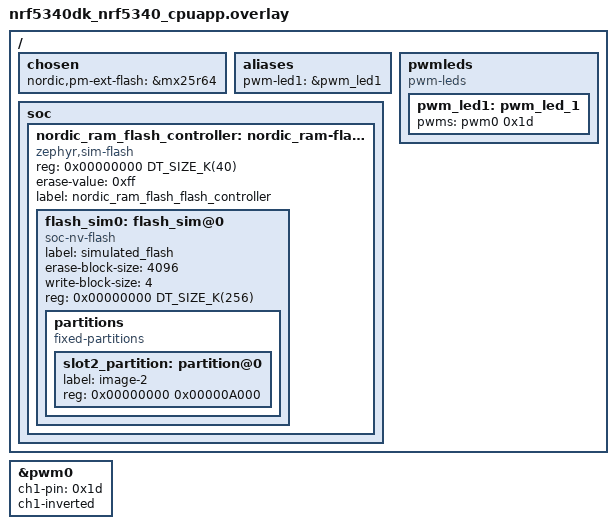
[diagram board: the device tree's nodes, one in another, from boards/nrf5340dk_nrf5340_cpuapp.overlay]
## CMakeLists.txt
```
#
# Copyright (c) 2021 Nordic Semiconductor ASA
#
# SPDX-License-Identifier: LicenseRef-Nordic-5-Clause
#

cmake_minimum_required(VERSION 3.20.0)

if(BOARD STREQUAL "nrf52840dk_nrf52840" OR BOARD STREQUAL "nrf5340dk_nrf5340_cpuapp")
    set(BUILD_WITH_DFU "MATTER" CACHE STRING "Build target with Device Firmware Upgrade support")
else()
    set(BUILD_WITH_DFU "OFF" CACHE STRING "Build target with Device Firmware Upgrade support")
endif()

if(NOT BUILD_WITH_DFU STREQUAL "OFF")
    if(BUILD_WITH_DFU STREQUAL "BLE" AND BOARD STREQUAL "nrf5340dk_nrf5340_cpuapp")
        set(CONF_FILE prj_multi_image_smp_dfu.conf)
    elseif(BUILD_WITH_DFU STREQUAL "BLE")
        set(CONF_FILE prj_single_image_smp_dfu.conf)
    elseif(BUILD_WITH_DFU STREQUAL "MATTER" AND BOARD STREQUAL "nrf5340dk_nrf5340_cpuapp")
        set(CONF_FILE prj_multi_image_matter_dfu.conf)
    elseif(BUILD_WITH_DFU STREQUAL "MATTER")
        set(CONF_FILE prj_single_image_matter_dfu.conf)
    else()
        message(FATAL_ERROR "Selected invalid BUILD_WITH_DFU value: ${BUILD_WITH_DFU}")
    endif()

    if (EXISTS "${CMAKE_CURRENT_SOURCE_DIR}/configuration/${BOARD}/pm_static.yml")
        set(PM_STATIC_YML_FILE ${CMAKE_CURRENT_SOURCE_DIR}/configuration/${BOARD}/pm_static.yml)
    else()
        message(FATAL_ERROR "The ${BOARD} target does not support DFU")
    endif()
endif()

find_package(Zephyr HINTS $ENV{ZEPHYR_BASE})

project(matter-light-bulb)

set(COMMON_ROOT ${ZEPHYR_NRF_MODULE_DIR}/samples/matter/common)
set(NLIO_ROOT ${ZEPHYR_CONNECTEDHOMEIP_MODULE_DIR}/third_party/nlio/repo)
include(${ZEPHYR_CONNECTEDHOMEIP_MODULE_DIR}/config/nrfconnect/app/enable-gnu-std.cmake)
include(${ZEPHYR_CONNECTEDHOMEIP_MODULE_DIR}/src/app/chip_data_model.cmake)

# NORDIC SDK APP START
target_include_directories(app PRIVATE
    src
    ${COMMON_ROOT}/src
    ${NLIO_ROOT}/include
    ${ZEPHYR_CONNECTEDHOMEIP_MODULE_DIR}/zzz_generated/app-common
)

target_sources(app PRIVATE
    src/app_task.cpp
    src/lighting_manager.cpp
    src/light_bulb_publish_service.cpp
    src/main.cpp
    src/zcl_callbacks.cpp
    src/zap-generated/IMClusterCommandHandler.cpp
    src/zap-generated/callback-stub.cpp
    ${COMMON_ROOT}/src/led_widget.cpp
    ${COMMON_ROOT}/src/thread_util.cpp
)

if(BUILD_WITH_DFU STREQUAL "BLE")
    target_sources(app PRIVATE ${COMMON_ROOT}/src/dfu_over_smp.cpp)
endif()

chip_configure_data_model(app
    INCLUDE_SERVER
    ZAP_FILE ${CMAKE_CURRENT_SOURCE_DIR}/src/light_bulb.zap
)
# NORDIC SDK APP END
```

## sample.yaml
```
sample:
  name: Matter Light Bulb
  description: Matter Light Bulb example
tests:
  matter.light_bulb:
    build_only: true
    platform_allow: nrf52840dk_nrf52840 nrf5340dk_nrf5340_cpuapp nrf21540dk_nrf52840
    integration_platforms:
      - nrf52840dk_nrf52840
      - nrf5340dk_nrf5340_cpuapp
      - nrf21540dk_nrf52840
    tags: ci_build
  matter.light_bulb.smp_dfu:
    build_only: true
    platform_allow: nrf52840dk_nrf52840 nrf5340dk_nrf5340_cpuapp
    integration_platforms:
      - nrf52840dk_nrf52840
      - nrf5340dk_nrf5340_cpuapp
    tags: ci_build
    extra_args: "BUILD_WITH_DFU=BLE"
```

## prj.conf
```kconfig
#
# Copyright (c) 2021 Nordic Semiconductor ASA
#
# SPDX-License-Identifier: LicenseRef-Nordic-5-Clause
#

# Enable CHIP
CONFIG_CHIP=y
CONFIG_CHIP_PROJECT_CONFIG="src/chip_project_config.h"
CONFIG_STD_CPP14=y

# Enable CHIP pairing automatically on application start.
CONFIG_CHIP_ENABLE_PAIRING_AUTOSTART=y

# General networking settings
CONFIG_NETWORKING=y
CONFIG_NET_IPV6_NBR_CACHE=n
CONFIG_NET_IPV6_MLD=n
CONFIG_NET_SOCKETS_POLL_MAX=5

# Enable OpenThread MTD
CONFIG_NET_L2_OPENTHREAD=y

CONFIG_OPENTHREAD_MTD=y
CONFIG_OPENTHREAD_FTD=n
CONFIG_OPENTHREAD_SLAAC=y
CONFIG_OPENTHREAD_MTD_NETDIAG=y
CONFIG_OPENTHREAD_MANUAL_START=y
CONFIG_OPENTHREAD_THREAD_STACK_SIZE=6144
CONFIG_OPENTHREAD_NUM_MESSAGE_BUFFERS=64

CONFIG_OPENTHREAD_PANID=4660
CONFIG_OPENTHREAD_CHANNEL=15
CONFIG_OPENTHREAD_NETWORK_NAME="OpenThread"
CONFIG_OPENTHREAD_XPANID="11:11:11:11:22:22:22:22"

# Enable Thread 1.2 features
CONFIG_OPENTHREAD_THREAD_VERSION_1_2=y
CONFIG_OPENTHREAD_DUA=y
CONFIG_OPENTHREAD_MLR=y

# Enable Bluetooth Low Energy
CONFIG_BT=y
CONFIG_BT_PERIPHERAL=y
CONFIG_BT_PERIPHERAL_PREF_MIN_INT=12
CONFIG_BT_PERIPHERAL_PREF_MAX_INT=12
CONFIG_BT_GAP_AUTO_UPDATE_CONN_PARAMS=y
CONFIG_BT_GATT_DYNAMIC_DB=y
CONFIG_BT_DEVICE_APPEARANCE=0
CONFIG_BT_DEVICE_NAME_DYNAMIC=y
CONFIG_BT_DEVICE_NAME_MAX=15
CONFIG_BT_DEVICE_NAME="MatterLight"
CONFIG_BT_MAX_CONN=1
CONFIG_BT_L2CAP_TX_MTU=247
CONFIG_BT_BUF_ACL_RX_SIZE=251
CONFIG_BT_BUF_ACL_TX_SIZE=251

# Use NFC to share commissioning information
CONFIG_CHIP_NFC_COMMISSIONING=y

# Use nrf_security
CONFIG_OPENTHREAD_NRF_SECURITY_CHOICE=y

CONFIG_CC3XX_BACKEND=n
CONFIG_OBERON_BACKEND=y

CONFIG_MBEDTLS_ENABLE_HEAP=y
CONFIG_MBEDTLS_HEAP_SIZE=15360
CONFIG_MBEDTLS_TLS_LIBRARY=y
CONFIG_NRF_SECURITY_ADVANCED=y

CONFIG_MBEDTLS_AES_C=y
CONFIG_MBEDTLS_ECP_C=y
CONFIG_MBEDTLS_ECP_DP_SECP256R1_ENABLED=y
CONFIG_MBEDTLS_CTR_DRBG_C=y
CONFIG_MBEDTLS_CIPHER_MODE_CTR=y
CONFIG_MBEDTLS_ECJPAKE_C=y
CONFIG_MBEDTLS_SHA256_C=y
CONFIG_MBEDTLS_PK_C=y
CONFIG_MBEDTLS_PK_WRITE_C=y
CONFIG_MBEDTLS_X509_CREATE_C=y
CONFIG_MBEDTLS_X509_CSR_WRITE_C=y

# Disable unneeded crypto operations
CONFIG_MBEDTLS_SHA384_C=n
CONFIG_MBEDTLS_SHA512_C=n
CONFIG_MBEDTLS_CIPHER_MODE_XTS=n
CONFIG_MBEDTLS_CHACHA20_C=n
CONFIG_MBEDTLS_POLY1305_C=n
CONFIG_MBEDTLS_CHACHAPOLY_C=n
CONFIG_MBEDTLS_GCM_C=n
CONFIG_MBEDTLS_RSA_C=n

# Add support for LEDs and buttons on Nordic development kits
CONFIG_DK_LIBRARY=y
CONFIG_PWM=y

# Other settings
CONFIG_LOG=y
CONFIG_LOG_MODE_MINIMAL=y
CONFIG_MATTER_LOG_LEVEL_DBG=y
CONFIG_PRINTK_SYNC=y
CONFIG_MAIN_STACK_SIZE=8192
CONFIG_INIT_STACKS=y
CONFIG_HW_STACK_PROTECTION=y
CONFIG_HWINFO=y
CONFIG_THREAD_NAME=y
CONFIG_SHELL=y
CONFIG_ASSERT=y
```

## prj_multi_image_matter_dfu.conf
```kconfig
#
# Copyright (c) 2022 Nordic Semiconductor ASA
#
# SPDX-License-Identifier: LicenseRef-Nordic-5-Clause
#

# Enable CHIP
CONFIG_CHIP=y
CONFIG_CHIP_PROJECT_CONFIG="src/chip_project_config.h"
CONFIG_STD_CPP14=y

# Enable CHIP pairing automatically on application start.
CONFIG_CHIP_ENABLE_PAIRING_AUTOSTART=y

# General networking settings
CONFIG_NETWORKING=y
CONFIG_NET_IPV6_NBR_CACHE=n
CONFIG_NET_IPV6_MLD=n
CONFIG_NET_SOCKETS_POLL_MAX=5

# Enable OpenThread MTD
CONFIG_NET_L2_OPENTHREAD=y

CONFIG_OPENTHREAD_MTD=y
CONFIG_OPENTHREAD_FTD=n
CONFIG_OPENTHREAD_SLAAC=y
CONFIG_OPENTHREAD_MTD_NETDIAG=y
CONFIG_OPENTHREAD_MANUAL_START=y
CONFIG_OPENTHREAD_THREAD_STACK_SIZE=6144
CONFIG_OPENTHREAD_NUM_MESSAGE_BUFFERS=64

CONFIG_OPENTHREAD_PANID=4660
CONFIG_OPENTHREAD_CHANNEL=15
CONFIG_OPENTHREAD_NETWORK_NAME="OpenThread"
CONFIG_OPENTHREAD_XPANID="11:11:11:11:22:22:22:22"

# Enable Thread 1.2 features
CONFIG_OPENTHREAD_THREAD_VERSION_1_2=y
CONFIG_OPENTHREAD_DUA=y
CONFIG_OPENTHREAD_MLR=y

# Enable Bluetooth Low Energy
CONFIG_BT=y
CONFIG_BT_PERIPHERAL=y
CONFIG_BT_PERIPHERAL_PREF_MIN_INT=12
CONFIG_BT_PERIPHERAL_PREF_MAX_INT=12
CONFIG_BT_GAP_AUTO_UPDATE_CONN_PARAMS=y
CONFIG_BT_GATT_DYNAMIC_DB=y
CONFIG_BT_DEVICE_APPEARANCE=0
CONFIG_BT_DEVICE_NAME_DYNAMIC=y
CONFIG_BT_DEVICE_NAME_MAX=15
CONFIG_BT_DEVICE_NAME="MatterLight"
CONFIG_BT_MAX_CONN=1
CONFIG_BT_L2CAP_TX_MTU=247
CONFIG_BT_BUF_ACL_RX_SIZE=251
CONFIG_BT_BUF_ACL_TX_SIZE=251

# Use NFC to share commissioning information
CONFIG_CHIP_NFC_COMMISSIONING=y

# Use nrf_security
CONFIG_OPENTHREAD_NRF_SECURITY_CHOICE=y

CONFIG_CC3XX_BACKEND=n
CONFIG_OBERON_BACKEND=y

CONFIG_MBEDTLS_ENABLE_HEAP=y
CONFIG_MBEDTLS_HEAP_SIZE=15360
CONFIG_MBEDTLS_TLS_LIBRARY=y
CONFIG_NRF_SECURITY_ADVANCED=y

CONFIG_MBEDTLS_AES_C=y
CONFIG_MBEDTLS_ECP_C=y
CONFIG_MBEDTLS_ECP_DP_SECP256R1_ENABLED=y
CONFIG_MBEDTLS_CTR_DRBG_C=y
CONFIG_MBEDTLS_CIPHER_MODE_CTR=y
CONFIG_MBEDTLS_ECJPAKE_C=y
CONFIG_MBEDTLS_SHA256_C=y
CONFIG_MBEDTLS_PK_C=y
CONFIG_MBEDTLS_PK_WRITE_C=y
CONFIG_MBEDTLS_X509_CREATE_C=y
CONFIG_MBEDTLS_X509_CSR_WRITE_C=y

# Disable unneeded crypto operations
CONFIG_MBEDTLS_SHA384_C=n
CONFIG_MBEDTLS_SHA512_C=n
CONFIG_MBEDTLS_CIPHER_MODE_XTS=n
CONFIG_MBEDTLS_CHACHA20_C=n
CONFIG_MBEDTLS_POLY1305_C=n
CONFIG_MBEDTLS_CHACHAPOLY_C=n
CONFIG_MBEDTLS_GCM_C=n
CONFIG_MBEDTLS_RSA_C=n

# Add support for LEDs and buttons on Nordic development kits
CONFIG_DK_LIBRARY=y
CONFIG_PWM=y

# Other settings
CONFIG_LOG=y
CONFIG_LOG_MODE_MINIMAL=y
CONFIG_MATTER_LOG_LEVEL_DBG=y
CONFIG_PRINTK_SYNC=y
CONFIG_MAIN_STACK_SIZE=8192
CONFIG_INIT_STACKS=y
CONFIG_HW_STACK_PROTECTION=y
CONFIG_HWINFO=y
CONFIG_THREAD_NAME=y
CONFIG_SHELL=y
CONFIG_ASSERT=y

# Enable bootloader and DFU related configs
CONFIG_BOOTLOADER_MCUBOOT=y
CONFIG_UPDATEABLE_IMAGE_NUMBER=2

# QSPI configuration
CONFIG_NORDIC_QSPI_NOR=y
CONFIG_NORDIC_QSPI_NOR_FLASH_LAYOUT_PAGE_SIZE=4096
CONFIG_NORDIC_QSPI_NOR_STACK_WRITE_BUFFER_SIZE=16

# FLASH nop device is needed to access network core image data.
CONFIG_FLASH_NOP_DEVICE=y

# Enable Matter OTA
CONFIG_CHIP_OTA_REQUESTOR=y
CONFIG_IMG_MANAGER=y
```

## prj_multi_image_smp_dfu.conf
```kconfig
#
# Copyright (c) 2021 Nordic Semiconductor ASA
#
# SPDX-License-Identifier: LicenseRef-Nordic-5-Clause
#

# Enable CHIP
CONFIG_CHIP=y
CONFIG_CHIP_PROJECT_CONFIG="src/chip_project_config.h"
CONFIG_STD_CPP14=y

# Enable CHIP pairing automatically on application start.
CONFIG_CHIP_ENABLE_PAIRING_AUTOSTART=y

# General networking settings
CONFIG_NETWORKING=y
CONFIG_NET_IPV6_NBR_CACHE=n
CONFIG_NET_IPV6_MLD=n
CONFIG_NET_SOCKETS_POLL_MAX=5

# Enable OpenThread MTD
CONFIG_NET_L2_OPENTHREAD=y

CONFIG_OPENTHREAD_MTD=y
CONFIG_OPENTHREAD_FTD=n
CONFIG_OPENTHREAD_SLAAC=y
CONFIG_OPENTHREAD_MTD_NETDIAG=y
CONFIG_OPENTHREAD_MANUAL_START=y
CONFIG_OPENTHREAD_THREAD_STACK_SIZE=6144
CONFIG_OPENTHREAD_NUM_MESSAGE_BUFFERS=64

CONFIG_OPENTHREAD_PANID=4660
CONFIG_OPENTHREAD_CHANNEL=15
CONFIG_OPENTHREAD_NETWORK_NAME="OpenThread"
CONFIG_OPENTHREAD_XPANID="11:11:11:11:22:22:22:22"

# Enable Thread 1.2 features
CONFIG_OPENTHREAD_THREAD_VERSION_1_2=y
CONFIG_OPENTHREAD_DUA=y
CONFIG_OPENTHREAD_MLR=y

# Enable Bluetooth Low Energy
CONFIG_BT=y
CONFIG_BT_PERIPHERAL=y
CONFIG_BT_PERIPHERAL_PREF_MIN_INT=12
CONFIG_BT_PERIPHERAL_PREF_MAX_INT=12
CONFIG_BT_GAP_AUTO_UPDATE_CONN_PARAMS=y
CONFIG_BT_GATT_DYNAMIC_DB=y
CONFIG_BT_DEVICE_APPEARANCE=0
CONFIG_BT_DEVICE_NAME_DYNAMIC=y
CONFIG_BT_DEVICE_NAME_MAX=15
CONFIG_BT_DEVICE_NAME="MatterLight"
CONFIG_BT_MAX_CONN=1

# Use NFC to share commissioning information
CONFIG_CHIP_NFC_COMMISSIONING=y

# Use nrf_security
CONFIG_OPENTHREAD_NRF_SECURITY_CHOICE=y

CONFIG_CC3XX_BACKEND=n
CONFIG_OBERON_BACKEND=y

CONFIG_MBEDTLS_ENABLE_HEAP=y
CONFIG_MBEDTLS_HEAP_SIZE=15360
CONFIG_MBEDTLS_TLS_LIBRARY=y
CONFIG_NRF_SECURITY_ADVANCED=y

CONFIG_MBEDTLS_AES_C=y
CONFIG_MBEDTLS_ECP_C=y
CONFIG_MBEDTLS_ECP_DP_SECP256R1_ENABLED=y
CONFIG_MBEDTLS_CTR_DRBG_C=y
CONFIG_MBEDTLS_CIPHER_MODE_CTR=y
CONFIG_MBEDTLS_ECJPAKE_C=y
CONFIG_MBEDTLS_SHA256_C=y
CONFIG_MBEDTLS_PK_C=y
CONFIG_MBEDTLS_PK_WRITE_C=y
CONFIG_MBEDTLS_X509_CREATE_C=y
CONFIG_MBEDTLS_X509_CSR_WRITE_C=y

# Disable unneeded crypto operations
CONFIG_MBEDTLS_SHA384_C=n
CONFIG_MBEDTLS_SHA512_C=n
CONFIG_MBEDTLS_CIPHER_MODE_XTS=n
CONFIG_MBEDTLS_CHACHA20_C=n
CONFIG_MBEDTLS_POLY1305_C=n
CONFIG_MBEDTLS_CHACHAPOLY_C=n
CONFIG_MBEDTLS_GCM_C=n
CONFIG_MBEDTLS_RSA_C=n

# Add support for LEDs and buttons on Nordic development kits
CONFIG_DK_LIBRARY=y
CONFIG_PWM=y

# Other settings
CONFIG_LOG=y
CONFIG_LOG_MODE_MINIMAL=y
CONFIG_MATTER_LOG_LEVEL_DBG=y
CONFIG_PRINTK_SYNC=y
CONFIG_MAIN_STACK_SIZE=8192
CONFIG_INIT_STACKS=y
CONFIG_HW_STACK_PROTECTION=y
CONFIG_HWINFO=y
CONFIG_THREAD_NAME=y
CONFIG_SHELL=y
CONFIG_ASSERT=y

# Enable bootloader and DFU related configs
CONFIG_BOOTLOADER_MCUBOOT=y
CONFIG_UPDATEABLE_IMAGE_NUMBER=2

# QSPI configuration
CONFIG_NORDIC_QSPI_NOR=y
CONFIG_NORDIC_QSPI_NOR_FLASH_LAYOUT_PAGE_SIZE=4096
CONFIG_NORDIC_QSPI_NOR_STACK_WRITE_BUFFER_SIZE=16

# MCU Manager and SMP configuration
CONFIG_MCUMGR=y
CONFIG_MCUMGR_CMD_IMG_MGMT=y
CONFIG_MCUMGR_CMD_OS_MGMT=y
CONFIG_MCUMGR_SMP_BT=y
CONFIG_MCUMGR_SMP_BT_AUTHEN=n
CONFIG_MCUMGR_BUF_COUNT=6

# Increase BT MTU and RX buffer for big size DFU messages
CONFIG_BT_L2CAP_TX_MTU=498
CONFIG_BT_BUF_ACL_TX_SIZE=251
CONFIG_BT_BUF_ACL_RX_SIZE=502

# Increase max number of pending GATT notification callbacks
CONFIG_BT_CONN_TX_MAX=6

# Increase system workqueue size, as SMP is processed within it
CONFIG_SYSTEM_WORKQUEUE_STACK_SIZE=2800

# FLASH nop device is enabled to prevent bus faults when mcumgr tries to access
# simulated partition with network core image data.
CONFIG_FLASH_NOP_DEVICE=y

# Enable custom SMP request to erase settings partition.
CONFIG_MCUMGR_GRP_ZEPHYR_BASIC=y
CONFIG_MCUMGR_GRP_BASIC_CMD_STORAGE_ERASE=y

# Enable Matter OTA
CONFIG_CHIP_OTA_REQUESTOR=y
```

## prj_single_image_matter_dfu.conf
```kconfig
#
# Copyright (c) 2022 Nordic Semiconductor ASA
#
# SPDX-License-Identifier: LicenseRef-Nordic-5-Clause
#

# Enable CHIP
CONFIG_CHIP=y
CONFIG_CHIP_PROJECT_CONFIG="src/chip_project_config.h"
CONFIG_STD_CPP14=y

# Enable CHIP pairing automatically on application start.
CONFIG_CHIP_ENABLE_PAIRING_AUTOSTART=y

# General networking settings
CONFIG_NETWORKING=y
CONFIG_NET_IPV6_NBR_CACHE=n
CONFIG_NET_IPV6_MLD=n
CONFIG_NET_SOCKETS_POLL_MAX=5

# Enable OpenThread MTD
CONFIG_NET_L2_OPENTHREAD=y

CONFIG_OPENTHREAD_MTD=y
CONFIG_OPENTHREAD_FTD=n
CONFIG_OPENTHREAD_SLAAC=y
CONFIG_OPENTHREAD_MTD_NETDIAG=y
CONFIG_OPENTHREAD_MANUAL_START=y
CONFIG_OPENTHREAD_THREAD_STACK_SIZE=6144
CONFIG_OPENTHREAD_NUM_MESSAGE_BUFFERS=64

CONFIG_OPENTHREAD_PANID=4660
CONFIG_OPENTHREAD_CHANNEL=15
CONFIG_OPENTHREAD_NETWORK_NAME="OpenThread"
CONFIG_OPENTHREAD_XPANID="11:11:11:11:22:22:22:22"

# Enable Thread 1.2 features
CONFIG_OPENTHREAD_THREAD_VERSION_1_2=y
CONFIG_OPENTHREAD_DUA=y
CONFIG_OPENTHREAD_MLR=y

# Enable Bluetooth Low Energy
CONFIG_BT=y
CONFIG_BT_PERIPHERAL=y
CONFIG_BT_PERIPHERAL_PREF_MIN_INT=12
CONFIG_BT_PERIPHERAL_PREF_MAX_INT=12
CONFIG_BT_GAP_AUTO_UPDATE_CONN_PARAMS=y
CONFIG_BT_GATT_DYNAMIC_DB=y
CONFIG_BT_DEVICE_APPEARANCE=0
CONFIG_BT_DEVICE_NAME_DYNAMIC=y
CONFIG_BT_DEVICE_NAME_MAX=15
CONFIG_BT_DEVICE_NAME="MatterLight"
CONFIG_BT_MAX_CONN=1
CONFIG_BT_L2CAP_TX_MTU=247
CONFIG_BT_BUF_ACL_RX_SIZE=251
CONFIG_BT_BUF_ACL_TX_SIZE=251

# Use NFC to share commissioning information
CONFIG_CHIP_NFC_COMMISSIONING=y

# Use nrf_security
CONFIG_OPENTHREAD_NRF_SECURITY_CHOICE=y

CONFIG_CC3XX_BACKEND=n
CONFIG_OBERON_BACKEND=y

CONFIG_MBEDTLS_ENABLE_HEAP=y
CONFIG_MBEDTLS_HEAP_SIZE=15360
CONFIG_MBEDTLS_TLS_LIBRARY=y
CONFIG_NRF_SECURITY_ADVANCED=y

CONFIG_MBEDTLS_AES_C=y
CONFIG_MBEDTLS_ECP_C=y
CONFIG_MBEDTLS_ECP_DP_SECP256R1_ENABLED=y
CONFIG_MBEDTLS_CTR_DRBG_C=y
CONFIG_MBEDTLS_CIPHER_MODE_CTR=y
CONFIG_MBEDTLS_ECJPAKE_C=y
CONFIG_MBEDTLS_SHA256_C=y
CONFIG_MBEDTLS_PK_C=y
CONFIG_MBEDTLS_PK_WRITE_C=y
CONFIG_MBEDTLS_X509_CREATE_C=y
CONFIG_MBEDTLS_X509_CSR_WRITE_C=y

# Disable unneeded crypto operations
CONFIG_MBEDTLS_SHA384_C=n
CONFIG_MBEDTLS_SHA512_C=n
CONFIG_MBEDTLS_CIPHER_MODE_XTS=n
CONFIG_MBEDTLS_CHACHA20_C=n
CONFIG_MBEDTLS_POLY1305_C=n
CONFIG_MBEDTLS_CHACHAPOLY_C=n
CONFIG_MBEDTLS_GCM_C=n
CONFIG_MBEDTLS_RSA_C=n

# Add support for LEDs and buttons on Nordic development kits
CONFIG_DK_LIBRARY=y
CONFIG_PWM=y

# Other settings
CONFIG_LOG=y
CONFIG_LOG_MODE_MINIMAL=y
CONFIG_MATTER_LOG_LEVEL_DBG=y
CONFIG_PRINTK_SYNC=y
CONFIG_MAIN_STACK_SIZE=8192
CONFIG_INIT_STACKS=y
CONFIG_HW_STACK_PROTECTION=y
CONFIG_HWINFO=y
CONFIG_THREAD_NAME=y
CONFIG_SHELL=y
CONFIG_ASSERT=y

# Enable bootloader and DFU related configs
CONFIG_BOOTLOADER_MCUBOOT=y

# QSPI configuration
CONFIG_NORDIC_QSPI_NOR=y
CONFIG_NORDIC_QSPI_NOR_FLASH_LAYOUT_PAGE_SIZE=4096
CONFIG_NORDIC_QSPI_NOR_STACK_WRITE_BUFFER_SIZE=16

# Enable Matter OTA
CONFIG_CHIP_OTA_REQUESTOR=y
CONFIG_IMG_MANAGER=y
```

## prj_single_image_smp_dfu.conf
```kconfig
#
# Copyright (c) 2021 Nordic Semiconductor ASA
#
# SPDX-License-Identifier: LicenseRef-Nordic-5-Clause
#

# Enable CHIP
CONFIG_CHIP=y
CONFIG_CHIP_PROJECT_CONFIG="src/chip_project_config.h"
CONFIG_STD_CPP14=y

# Enable CHIP pairing automatically on application start.
CONFIG_CHIP_ENABLE_PAIRING_AUTOSTART=y

# General networking settings
CONFIG_NETWORKING=y
CONFIG_NET_IPV6_NBR_CACHE=n
CONFIG_NET_IPV6_MLD=n
CONFIG_NET_SOCKETS_POLL_MAX=5

# Enable OpenThread MTD
CONFIG_NET_L2_OPENTHREAD=y

CONFIG_OPENTHREAD_MTD=y
CONFIG_OPENTHREAD_FTD=n
CONFIG_OPENTHREAD_SLAAC=y
CONFIG_OPENTHREAD_MTD_NETDIAG=y
CONFIG_OPENTHREAD_MANUAL_START=y
CONFIG_OPENTHREAD_THREAD_STACK_SIZE=6144
CONFIG_OPENTHREAD_NUM_MESSAGE_BUFFERS=64

CONFIG_OPENTHREAD_PANID=4660
CONFIG_OPENTHREAD_CHANNEL=15
CONFIG_OPENTHREAD_NETWORK_NAME="OpenThread"
CONFIG_OPENTHREAD_XPANID="11:11:11:11:22:22:22:22"

# Enable Thread 1.2 features
CONFIG_OPENTHREAD_THREAD_VERSION_1_2=y
CONFIG_OPENTHREAD_DUA=y
CONFIG_OPENTHREAD_MLR=y

# Enable Bluetooth Low Energy
CONFIG_BT=y
CONFIG_BT_PERIPHERAL=y
CONFIG_BT_PERIPHERAL_PREF_MIN_INT=12
CONFIG_BT_PERIPHERAL_PREF_MAX_INT=12
CONFIG_BT_GAP_AUTO_UPDATE_CONN_PARAMS=y
CONFIG_BT_GATT_DYNAMIC_DB=y
CONFIG_BT_DEVICE_APPEARANCE=0
CONFIG_BT_DEVICE_NAME_DYNAMIC=y
CONFIG_BT_DEVICE_NAME_MAX=15
CONFIG_BT_DEVICE_NAME="MatterLight"
CONFIG_BT_MAX_CONN=1

# Use NFC to share commissioning information
CONFIG_CHIP_NFC_COMMISSIONING=y

# Use nrf_security
CONFIG_OPENTHREAD_NRF_SECURITY_CHOICE=y

CONFIG_CC3XX_BACKEND=n
CONFIG_OBERON_BACKEND=y

CONFIG_MBEDTLS_ENABLE_HEAP=y
CONFIG_MBEDTLS_HEAP_SIZE=15360
CONFIG_MBEDTLS_TLS_LIBRARY=y
CONFIG_NRF_SECURITY_ADVANCED=y

CONFIG_MBEDTLS_AES_C=y
CONFIG_MBEDTLS_ECP_C=y
CONFIG_MBEDTLS_ECP_DP_SECP256R1_ENABLED=y
CONFIG_MBEDTLS_CTR_DRBG_C=y
CONFIG_MBEDTLS_CIPHER_MODE_CTR=y
CONFIG_MBEDTLS_ECJPAKE_C=y
CONFIG_MBEDTLS_SHA256_C=y
CONFIG_MBEDTLS_PK_C=y
CONFIG_MBEDTLS_PK_WRITE_C=y
CONFIG_MBEDTLS_X509_CREATE_C=y
CONFIG_MBEDTLS_X509_CSR_WRITE_C=y

# Disable unneeded crypto operations
CONFIG_MBEDTLS_SHA384_C=n
CONFIG_MBEDTLS_SHA512_C=n
CONFIG_MBEDTLS_CIPHER_MODE_XTS=n
CONFIG_MBEDTLS_CHACHA20_C=n
CONFIG_MBEDTLS_POLY1305_C=n
CONFIG_MBEDTLS_CHACHAPOLY_C=n
CONFIG_MBEDTLS_GCM_C=n
CONFIG_MBEDTLS_RSA_C=n

# Add support for LEDs and buttons on Nordic development kits
CONFIG_DK_LIBRARY=y
CONFIG_PWM=y

# Other settings
CONFIG_LOG=y
CONFIG_LOG_MODE_MINIMAL=y
CONFIG_MATTER_LOG_LEVEL_DBG=y
CONFIG_PRINTK_SYNC=y
CONFIG_MAIN_STACK_SIZE=8192
CONFIG_INIT_STACKS=y
CONFIG_HW_STACK_PROTECTION=y
CONFIG_HWINFO=y
CONFIG_THREAD_NAME=y
CONFIG_SHELL=y
CONFIG_ASSERT=y

# Enable bootloader and DFU related configs
CONFIG_BOOTLOADER_MCUBOOT=y

# QSPI configuration
CONFIG_NORDIC_QSPI_NOR=y
CONFIG_NORDIC_QSPI_NOR_FLASH_LAYOUT_PAGE_SIZE=4096
CONFIG_NORDIC_QSPI_NOR_STACK_WRITE_BUFFER_SIZE=16

# MCU Manager and SMP configuration
CONFIG_MCUMGR=y
CONFIG_MCUMGR_CMD_IMG_MGMT=y
CONFIG_MCUMGR_CMD_OS_MGMT=y
CONFIG_MCUMGR_SMP_BT=y
CONFIG_MCUMGR_SMP_BT_AUTHEN=n
CONFIG_MCUMGR_BUF_COUNT=6

# Increase BT MTU and RX buffer for big size DFU messages
CONFIG_BT_L2CAP_TX_MTU=498
CONFIG_BT_BUF_ACL_TX_SIZE=251
CONFIG_BT_BUF_ACL_RX_SIZE=502

# Increase max number of pending GATT notification callbacks
CONFIG_BT_CONN_TX_MAX=6

# Increase MCUMGR_BUF_SIZE, as it must be big enough to fit MAX MTU + overhead and for single-image DFU default is 384 B
CONFIG_MCUMGR_BUF_SIZE=1024

# Increase system workqueue size, as SMP is processed within it
CONFIG_SYSTEM_WORKQUEUE_STACK_SIZE=2800

# Enable Matter OTA
CONFIG_CHIP_OTA_REQUESTOR=y
```

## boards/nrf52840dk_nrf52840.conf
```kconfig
#
# Copyright (c) 2021 Nordic Semiconductor ASA
#
# SPDX-License-Identifier: LicenseRef-Nordic-5-Clause
#

# Increase maximum data length of PDU supported in the Controller
CONFIG_BT_CTLR_DATA_LENGTH_MAX=251
```

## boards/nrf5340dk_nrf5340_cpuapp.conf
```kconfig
#
# Copyright (c) 2021 Nordic Semiconductor ASA
#
# SPDX-License-Identifier: LicenseRef-Nordic-5-Clause
#

# Generate random numbers using Xoroshiro algorithm instead of direct calls
# to the cryptocell library to workaround firmware hangs.
CONFIG_XOROSHIRO_RANDOM_GENERATOR=y
```

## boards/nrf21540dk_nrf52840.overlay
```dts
/*
 * Copyright (c) 2021 Nordic Semiconductor ASA
 *
 * SPDX-License-Identifier: LicenseRef-Nordic-5-Clause
 */

/ {
	/*
	* In some default configurations within the nRF Connect SDK,
	* e.g. on nRF52840, the chosen zephyr,entropy node is &cryptocell.
	* This devicetree overlay ensures that default is overridden wherever it
	* is set, as this application uses the RNG node for entropy exclusively.
	*/

	chosen {
		zephyr,entropy = &rng;
	};

	/*
	* By default, PWM module is only configured for led0 (LED1 on the board).
	* The lighting-app, however, uses LED2 to show the state of the lighting,
	* including its brightness level.
	*/
	aliases {
		pwm-led1 = &pwm_led1;
	};

	pwmleds {
		pwm_led1: pwm_led_1 {
			pwms = < &pwm0 0xe >;
		};
	};

};

&pwm0 {
	/delete-property/ ch0-pin;
	/delete-property/ ch0-inverted;
	ch1-pin = < 0xe >;
	ch1-inverted;
};
```

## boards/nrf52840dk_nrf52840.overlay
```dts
/*
 * Copyright (c) 2021 Nordic Semiconductor ASA
 *
 * SPDX-License-Identifier: LicenseRef-Nordic-5-Clause
 */

/ {
	chosen {
		nordic,pm-ext-flash = &mx25r64;
	};
};

/ {
	/*
	* In some default configurations within the nRF Connect SDK,
	* e.g. on nRF52840, the chosen zephyr,entropy node is &cryptocell.
	* This devicetree overlay ensures that default is overridden wherever it
	* is set, as this application uses the RNG node for entropy exclusively.
	*/

	chosen {
		zephyr,entropy = &rng;
	};

	/*
	* By default, PWM module is only configured for led0 (LED1 on the board).
	* The lighting-app, however, uses LED2 to show the state of the lighting,
	* including its brightness level.
	*/
	aliases {
		pwm-led1 = &pwm_led1;
	};

	pwmleds {
		pwm_led1: pwm_led_1 {
			pwms = < &pwm0 0xe >;
		};
	};

};

&pwm0 {
	/delete-property/ ch0-pin;
	/delete-property/ ch0-inverted;
	ch1-pin = < 0xe >;
	ch1-inverted;
};
```

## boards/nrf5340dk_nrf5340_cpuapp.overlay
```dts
/*
 * Copyright (c) 2021 Nordic Semiconductor ASA
 *
 * SPDX-License-Identifier: LicenseRef-Nordic-5-Clause
 */

/ {
	chosen {
		nordic,pm-ext-flash = &mx25r64;
	};
};

/ {
	/*
	* By default, PWM module is only configured for led0 (LED1 on the board).
	* The lighting-app, however, uses LED2 to show the state of the lighting,
	* including its brightness level.
	*/
	aliases {
		pwm-led1 = &pwm_led1;
	};

	pwmleds {
		compatible = "pwm-leds";
		pwm_led1: pwm_led_1 {
			pwms = < &pwm0 0x1d >;
		};
	};

	soc {
		/* Add a flash controller which has the compatible
		 * 'zephyr,sim-flash'. This will ensure that the flash
		 * simulator can use it. None of the other properties in this
		 * node is used for anything.
		 */
		nordic_ram_flash_controller: nordic_ram-flash-controller@0 {
			compatible = "zephyr,sim-flash";
			reg = <0x00000000 DT_SIZE_K(40)>;
			#address-cells = <1>;
			#size-cells = <1>;
			erase-value = <0xff>;
			label = "nordic_ram_flash_flash_controller";

			/* This node label must match that used in the flash
			 * simulator.
			 */
			flash_sim0: flash_sim@0 {
				status = "okay";
				compatible = "soc-nv-flash";
				label = "simulated_flash";
				erase-block-size = <4096>;
				write-block-size = <4>;
				reg = <0x00000000 DT_SIZE_K(256)>;

				partitions {
					compatible = "fixed-partitions";
					#address-cells = <1>;
					#size-cells = <1>;

					/* This partition must be defined for
					 * MCUboot to find the partition ID
					 * of the primary slot for image 1,
					 * which is stored in this partition.
					 */
					slot2_partition: partition@0 {
						label = "image-2";
						reg = <0x00000000 0x00000A000>;
					};
				};
			};
		};
	};

};

&pwm0 {
	/delete-property/ ch0-pin;
	/delete-property/ ch0-inverted;
	ch1-pin = < 0x1d >;
	ch1-inverted;
};
```

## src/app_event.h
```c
/*
 * Copyright (c) 2021 Nordic Semiconductor ASA
 *
 * SPDX-License-Identifier: LicenseRef-Nordic-5-Clause
 */

#pragma once

#include <cstdint>

#include "led_widget.h"

struct AppEvent {
	enum LightEventType : uint8_t { On, Off, Toggle, Level };

	enum FunctionEventType : uint8_t { FunctionPress = Level + 1, FunctionRelease, FunctionTimer };

	enum UpdateLedStateEventType : uint8_t { UpdateLedState = FunctionTimer + 1 };

	enum OtherEventType : uint8_t {
		StartThread = UpdateLedState + 1,
		StartBleAdvertising,
		PublishLightBulbService,
#ifdef CONFIG_MCUMGR_SMP_BT
		StartSMPAdvertising
#endif
	};

	AppEvent() = default;

	AppEvent(LightEventType type, uint8_t value, bool chipInitiated)
		: Type(type), LightEvent{ value, chipInitiated }
	{
	}

	AppEvent(FunctionEventType type) : Type(type) {}

	AppEvent(UpdateLedStateEventType type, LEDWidget *ledWidget) : Type(type), UpdateLedStateEvent{ ledWidget } {}

	AppEvent(OtherEventType type) : Type(type) {}

	uint8_t Type;

	union {
		struct {
			/* value indicating light brightness in the scope (0-255) */
			uint8_t Value;
			/* was the event triggered by CHIP Data Model layer */
			bool ChipInitiated;
		} LightEvent;
		struct {
			LEDWidget *LedWidget;
		} UpdateLedStateEvent;
	};
};
```

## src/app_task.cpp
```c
/*
 * Copyright (c) 2021 Nordic Semiconductor ASA
 *
 * SPDX-License-Identifier: LicenseRef-Nordic-5-Clause
 */

#include "app_task.h"

#include "led_widget.h"
#include "light_bulb_publish_service.h"
#include "lighting_manager.h"
#include "thread_util.h"

#include <platform/CHIPDeviceLayer.h>

#include <app-common/zap-generated/attribute-id.h>
#include <app-common/zap-generated/attribute-type.h>
#include <app-common/zap-generated/attributes/Accessors.h>
#include <app-common/zap-generated/cluster-id.h>
#include <app/server/OnboardingCodesUtil.h>
#include <app/server/Server.h>
#include <credentials/DeviceAttestationCredsProvider.h>
#include <credentials/examples/DeviceAttestationCredsExample.h>

#ifdef CONFIG_CHIP_OTA_REQUESTOR
#include <app/clusters/ota-requestor/BDXDownloader.h>
#include <app/clusters/ota-requestor/OTARequestor.h>
#include <platform/GenericOTARequestorDriver.h>
#include <platform/nrfconnect/OTAImageProcessorImpl.h>
#endif

#include <dk_buttons_and_leds.h>
#include <logging/log.h>
#include <zephyr.h>

#include <algorithm>

using namespace ::chip;
using namespace ::chip::app;
using namespace ::chip::Credentials;
using namespace ::chip::DeviceLayer;

#define PWM_DEVICE DEVICE_DT_GET(DT_PWMS_CTLR(DT_ALIAS(pwm_led1)))
#define PWM_CHANNEL DT_PWMS_CHANNEL(DT_ALIAS(pwm_led1))

LOG_MODULE_DECLARE(app);
K_MSGQ_DEFINE(sAppEventQueue, sizeof(AppEvent), AppTask::APP_EVENT_QUEUE_SIZE, alignof(AppEvent));

namespace
{
constexpr uint32_t kFactoryResetTriggerTimeout = 3000;
constexpr uint32_t kFactoryResetCancelWindow = 3000;
constexpr EndpointId kLightEndpointId = 1;
constexpr uint8_t kDefaultMinLevel = 0;
constexpr uint8_t kDefaultMaxLevel = 254;

LEDWidget sStatusLED;
LEDWidget sLightLED;
LEDWidget sUnusedLED;
LEDWidget sUnusedLED_1;

LightBulbPublishService sLightBulbPublishService;

bool sIsThreadProvisioned;
bool sIsThreadEnabled;
bool sHaveBLEConnections;

k_timer sFunctionTimer;

#ifdef CONFIG_CHIP_OTA_REQUESTOR
GenericOTARequestorDriver sOTARequestorDriver;
OTAImageProcessorImpl sOTAImageProcessor;
chip::BDXDownloader sBDXDownloader;
chip::OTARequestor sOTARequestor;
#endif
} /* namespace */

AppTask AppTask::sAppTask;

int AppTask::Init()
{
	/* Initialize LEDs */
	LEDWidget::InitGpio();
	LEDWidget::SetStateUpdateCallback(LEDStateUpdateHandler);

	sStatusLED.Init(DK_LED1);
	sLightLED.Init(DK_LED2);
	sLightLED.Set(false);
	sUnusedLED.Init(DK_LED3);
	sUnusedLED_1.Init(DK_LED4);

	UpdateStatusLED();

	/* Initialize buttons */
	int ret = dk_buttons_init(ButtonEventHandler);
	if (ret) {
		LOG_ERR("dk_buttons_init() failed");
		return ret;
	}

#ifdef CONFIG_MCUMGR_SMP_BT
	GetDFUOverSMP().Init(RequestSMPAdvertisingStart);
	GetDFUOverSMP().ConfirmNewImage();
#endif

	/* Initialize function timer */
	k_timer_init(&sFunctionTimer, &AppTask::TimerEventHandler, nullptr);
	k_timer_user_data_set(&sFunctionTimer, this);

	/* Initialize light manager */
	uint8_t minLightLevel = kDefaultMinLevel;
	Clusters::LevelControl::Attributes::MinLevel::Get(kLightEndpointId, &minLightLevel);

	uint8_t maxLightLevel = kDefaultMaxLevel;
	Clusters::LevelControl::Attributes::MaxLevel::Get(kLightEndpointId, &maxLightLevel);

	ret = LightingMgr().Init(PWM_DEVICE, PWM_CHANNEL, minLightLevel, maxLightLevel);
	if (ret) {
		return ret;
	}

	LightingMgr().SetCallbacks(ActionInitiated, ActionCompleted);

	/* Init ZCL Data Model and start server */
	chip::Server::GetInstance().Init();

	/* Initialize device attestation config */
	SetDeviceAttestationCredentialsProvider(Examples::GetExampleDACProvider());
	ConfigurationMgr().LogDeviceConfig();
	PrintOnboardingCodes(chip::RendezvousInformationFlags(chip::RendezvousInformationFlag::kBLE));

	PlatformMgr().AddEventHandler(AppTask::ChipEventHandler, 0);

#ifdef CONFIG_CHIP_OTA_REQUESTOR
	sOTAImageProcessor.SetOTADownloader(&sBDXDownloader);
	sBDXDownloader.SetImageProcessorDelegate(&sOTAImageProcessor);
	sOTARequestorDriver.Init(&sOTARequestor, &sOTAImageProcessor);
	sOTARequestor.Init(&chip::Server::GetInstance(), &sOTARequestorDriver, &sBDXDownloader);
	chip::SetRequestorInstance(&sOTARequestor);
#endif

	sLightBulbPublishService.Init();
	return 0;
}

int AppTask::StartApp()
{
	int ret = Init();

	if (ret) {
		LOG_ERR("AppTask.Init() failed");
		return ret;
	}

	AppEvent event = {};

	while (true) {
		k_msgq_get(&sAppEventQueue, &event, K_FOREVER);
		DispatchEvent(event);
	}
}

void AppTask::PostEvent(const AppEvent &aEvent)
{
	if (k_msgq_put(&sAppEventQueue, &aEvent, K_NO_WAIT)) {
		LOG_INF("Failed to post event to app task event queue");
	}
}

void AppTask::UpdateClusterState()
{
	/* write the new on/off value */

	EmberAfStatus status = Clusters::OnOff::Attributes::OnOff::Set(kLightEndpointId, LightingMgr().IsTurnedOn());

	if (status != EMBER_ZCL_STATUS_SUCCESS) {
		LOG_ERR("Updating on/off cluster failed: %x", status);
	}

	/* write the current level */

	status = Clusters::LevelControl::Attributes::CurrentLevel::Set(kLightEndpointId, LightingMgr().GetLevel());

	if (status != EMBER_ZCL_STATUS_SUCCESS) {
		LOG_ERR("Updating level cluster failed: %x", status);
	}
}

#ifdef CONFIG_MCUMGR_SMP_BT
void AppTask::RequestSMPAdvertisingStart(void)
{
	sAppTask.PostEvent(AppEvent{ AppEvent::StartSMPAdvertising });
}
#endif

void AppTask::DispatchEvent(const AppEvent &aEvent)
{
	switch (aEvent.Type) {
	case AppEvent::On:
		LightingMgr().InitiateAction(LightingManager::Action::On, aEvent.LightEvent.Value,
					     aEvent.LightEvent.ChipInitiated);
		break;
	case AppEvent::Off:
		LightingMgr().InitiateAction(LightingManager::Action::Off, aEvent.LightEvent.Value,
					     aEvent.LightEvent.ChipInitiated);
		break;
	case AppEvent::Toggle:
		LightingMgr().InitiateAction(LightingMgr().IsTurnedOn() ? LightingManager::Action::Off :
										LightingManager::Action::On,
					     aEvent.LightEvent.Value, aEvent.LightEvent.ChipInitiated);
		break;
	case AppEvent::Level:
		LightingMgr().InitiateAction(LightingManager::Action::Level, aEvent.LightEvent.Value,
					     aEvent.LightEvent.ChipInitiated);
		break;
	case AppEvent::FunctionPress:
		FunctionPressHandler();
		break;
	case AppEvent::FunctionRelease:
		FunctionReleaseHandler();
		break;
	case AppEvent::FunctionTimer:
		FunctionTimerEventHandler();
		break;
	case AppEvent::StartThread:
		StartThreadHandler();
		break;
	case AppEvent::StartBleAdvertising:
		StartBLEAdvertisingHandler();
		break;
	case AppEvent::UpdateLedState:
		aEvent.UpdateLedStateEvent.LedWidget->UpdateState();
		break;
#ifdef CONFIG_MCUMGR_SMP_BT
	case AppEvent::StartSMPAdvertising:
		GetDFUOverSMP().StartBLEAdvertising();
		break;
#endif
	case AppEvent::PublishLightBulbService:
		sLightBulbPublishService.Publish();
		break;
	default:
		LOG_INF("Unknown event received");
		break;
	}
}

void AppTask::ActionInitiated(LightingManager::Action aAction)
{
	if (aAction == LightingManager::Action::On) {
		LOG_INF("Turn On Action has been initiated");
	} else if (aAction == LightingManager::Action::Off) {
		LOG_INF("Turn Off Action has been initiated");
	} else if (aAction == LightingManager::Action::Level) {
		LOG_INF("Level Action has been initiated");
	}
}

void AppTask::ActionCompleted(LightingManager::Action aAction)
{
	if (aAction == LightingManager::Action::On) {
		LOG_INF("Turn On Action has been completed");
	} else if (aAction == LightingManager::Action::Off) {
		LOG_INF("Turn Off Action has been completed");
	} else if (aAction == LightingManager::Action::Level) {
		LOG_INF("Level Action has been completed");
	}

	if (!LightingMgr().IsActionChipInitiated()) {
		sAppTask.UpdateClusterState();
	}
}

void AppTask::FunctionPressHandler()
{
	sAppTask.StartFunctionTimer(kFactoryResetTriggerTimeout);
	sAppTask.mFunction = TimerFunction::SoftwareUpdate;
}

void AppTask::FunctionReleaseHandler()
{
	if (sAppTask.mFunction == TimerFunction::SoftwareUpdate) {
		sAppTask.CancelFunctionTimer();
		sAppTask.mFunction = TimerFunction::NoneSelected;

#ifdef CONFIG_MCUMGR_SMP_BT
		GetDFUOverSMP().StartServer();
#else
		LOG_INF("Software update is disabled");
#endif

	} else if (sAppTask.mFunction == TimerFunction::FactoryReset) {
		sUnusedLED_1.Set(false);
		sUnusedLED.Set(false);

		UpdateStatusLED();

		sAppTask.CancelFunctionTimer();
		sAppTask.mFunction = TimerFunction::NoneSelected;
		LOG_INF("Factory Reset has been Canceled");
	}
}

void AppTask::FunctionTimerEventHandler()
{
	if (sAppTask.mFunction == TimerFunction::SoftwareUpdate) {
		LOG_INF("Factory Reset Triggered. Release button within %ums to cancel.", kFactoryResetCancelWindow);
		sAppTask.StartFunctionTimer(kFactoryResetCancelWindow);
		sAppTask.mFunction = TimerFunction::FactoryReset;

		/* Turn off all LEDs before starting blink to make sure blink is co-ordinated. */
		sStatusLED.Set(false);
		sUnusedLED_1.Set(false);
		sUnusedLED.Set(false);

		sStatusLED.Blink(500);
		sUnusedLED.Blink(500);
		sUnusedLED_1.Blink(500);

	} else if (sAppTask.mFunction == TimerFunction::FactoryReset) {
		sAppTask.mFunction = TimerFunction::NoneSelected;
		LOG_INF("Factory Reset triggered");
		ConfigurationMgr().InitiateFactoryReset();
	}
}

void AppTask::StartThreadHandler()
{
	if (chip::Server::GetInstance().AddTestCommissioning() != CHIP_NO_ERROR) {
		LOG_ERR("Failed to add test pairing");
	}

	if (!ConnectivityMgr().IsThreadProvisioned()) {
		StartDefaultThreadNetwork();
		LOG_INF("Device is not commissioned to a Thread network. Starting with the default configuration");
	} else {
		LOG_INF("Device is commissioned to a Thread network");
	}

	sLightBulbPublishService.Start(10000, 1000);
}

void AppTask::StartBLEAdvertisingHandler()
{
	/* Don't allow on starting Matter service BLE advertising after Thread provisioning. */
	if (ConnectivityMgr().IsThreadProvisioned()) {
		LOG_INF("NFC Tag emulation and Matter service BLE advertising not started - device is commissioned to a Thread network.");
		return;
	}

	if (ConnectivityMgr().IsBLEAdvertisingEnabled()) {
		LOG_INF("BLE advertising is already enabled");
		return;
	}

	if (chip::Server::GetInstance().GetCommissioningWindowManager().OpenBasicCommissioningWindow() !=
	    CHIP_NO_ERROR) {
		LOG_ERR("OpenBasicCommissioningWindow() failed");
	}
}

void AppTask::LEDStateUpdateHandler(LEDWidget &ledWidget)
{
	sAppTask.PostEvent(AppEvent{ AppEvent::UpdateLedState, &ledWidget });
}

void AppTask::UpdateStatusLED()
{
	/* Update the status LED.
	 *
	 * If thread and service provisioned, keep the LED On constantly.
	 *
	 * If the system has ble connection(s) uptill the stage above, THEN blink the LED at an even
	 * rate of 100ms.
	 *
	 * Otherwise, blink the LED On for a very short time. */
	if (sIsThreadProvisioned && sIsThreadEnabled) {
		sStatusLED.Set(true);
	} else if (sHaveBLEConnections) {
		sStatusLED.Blink(100, 100);
	} else {
		sStatusLED.Blink(50, 950);
	}
}

void AppTask::ChipEventHandler(const ChipDeviceEvent *event, intptr_t /* arg */)
{
	switch (event->Type) {
	case DeviceEventType::kCHIPoBLEAdvertisingChange:
#ifdef CONFIG_CHIP_NFC_COMMISSIONING
		if (event->CHIPoBLEAdvertisingChange.Result == kActivity_Started) {
			if (NFCMgr().IsTagEmulationStarted()) {
				LOG_INF("NFC Tag emulation is already started");
			} else {
				ShareQRCodeOverNFC(
					chip::RendezvousInformationFlags(chip::RendezvousInformationFlag::kBLE));
			}
		} else if (event->CHIPoBLEAdvertisingChange.Result == kActivity_Stopped) {
			NFCMgr().StopTagEmulation();
		}
#endif
		sHaveBLEConnections = ConnectivityMgr().NumBLEConnections() != 0;
		UpdateStatusLED();
		break;
	case DeviceEventType::kThreadStateChange:
		sIsThreadProvisioned = ConnectivityMgr().IsThreadProvisioned();
		sIsThreadEnabled = ConnectivityMgr().IsThreadEnabled();
		UpdateStatusLED();
		break;
	default:
		break;
	}
}

void AppTask::ButtonEventHandler(uint32_t buttonState, uint32_t hasChanged)
{
	if (DK_BTN1_MSK & buttonState & hasChanged) {
		GetAppTask().PostEvent(AppEvent{ AppEvent::FunctionPress });
	} else if (DK_BTN1_MSK & hasChanged) {
		GetAppTask().PostEvent(AppEvent{ AppEvent::FunctionRelease });
	}

	if (DK_BTN2_MSK & buttonState & hasChanged) {
		GetAppTask().PostEvent(AppEvent{ AppEvent::Toggle, 0, false });
	}

	if (DK_BTN3_MSK & buttonState & hasChanged) {
		GetAppTask().PostEvent(AppEvent{ AppEvent::StartThread });
	}

	if (DK_BTN4_MSK & buttonState & hasChanged) {
		GetAppTask().PostEvent(AppEvent{ AppEvent::StartBleAdvertising });
	}
}

void AppTask::CancelFunctionTimer()
{
	k_timer_stop(&sFunctionTimer);
}

void AppTask::StartFunctionTimer(uint32_t timeoutInMs)
{
	k_timer_start(&sFunctionTimer, K_MSEC(timeoutInMs), K_NO_WAIT);
}

void AppTask::TimerEventHandler(k_timer *timer)
{
	GetAppTask().PostEvent(AppEvent{ AppEvent::FunctionTimer });
}
```

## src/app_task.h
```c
/*
 * Copyright (c) 2021 Nordic Semiconductor ASA
 *
 * SPDX-License-Identifier: LicenseRef-Nordic-5-Clause
 */

#pragma once

#include "app_event.h"
#include "led_widget.h"
#include "lighting_manager.h"

#include <platform/CHIPDeviceLayer.h>

#ifdef CONFIG_MCUMGR_SMP_BT
#include "dfu_over_smp.h"
#endif

struct k_timer;

class AppTask {
public:
	static constexpr size_t APP_EVENT_QUEUE_SIZE = 10;

	int StartApp();

	void PostEvent(const AppEvent &aEvent);
	void UpdateClusterState();

private:
	int Init();

	void CancelFunctionTimer();
	void StartFunctionTimer(uint32_t timeoutInMs);

	void DispatchEvent(const AppEvent &event);
	void FunctionPressHandler();
	void FunctionReleaseHandler();
	void FunctionTimerEventHandler();
	void StartThreadHandler();
	void StartBLEAdvertisingHandler();

	static void ActionInitiated(LightingManager::Action aAction);
	static void ActionCompleted(LightingManager::Action aAction);
	static void UpdateStatusLED();
	static void ButtonEventHandler(uint32_t buttonState, uint32_t hasChanged);
	static void TimerEventHandler(k_timer *timer);
	static void LEDStateUpdateHandler(LEDWidget &ledWidget);
	static void ChipEventHandler(const chip::DeviceLayer::ChipDeviceEvent *event, intptr_t arg);
#ifdef CONFIG_MCUMGR_SMP_BT
	static void RequestSMPAdvertisingStart(void);
#endif

	friend AppTask &GetAppTask();

	enum class TimerFunction { NoneSelected = 0, SoftwareUpdate, FactoryReset };

	TimerFunction mFunction = TimerFunction::NoneSelected;

	static AppTask sAppTask;
};

inline AppTask &GetAppTask()
{
	return AppTask::sAppTask;
}
```

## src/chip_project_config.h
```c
/*
 * Copyright (c) 2021 Nordic Semiconductor ASA
 *
 * SPDX-License-Identifier: LicenseRef-Nordic-5-Clause
 */

/**
 *    @file
 *          Example project configuration file for CHIP.
 *
 *          This is a place to put application or project-specific overrides
 *          to the default configuration values for general CHIP features.
 *
 */

#pragma once

/**
 * CHIP_DEVICE_CONFIG_DEVICE_PRODUCT_ID
 *
 * 0x4E4C: nrfconnect light_bulb
 */
#define CHIP_DEVICE_CONFIG_DEVICE_PRODUCT_ID 0x4E4C

/* Use a default pairing code if one hasn't been provisioned in flash. */
#define CHIP_DEVICE_CONFIG_USE_TEST_SETUP_PIN_CODE 20202021
#define CHIP_DEVICE_CONFIG_USE_TEST_SETUP_DISCRIMINATOR 0xF00
```

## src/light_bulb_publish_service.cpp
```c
/*
 * Copyright (c) 2021 Nordic Semiconductor ASA
 *
 * SPDX-License-Identifier: LicenseRef-Nordic-5-Clause
 */

#include "light_bulb_publish_service.h"

#include "app_task.h"

#include <logging/log.h>
#include <zephyr.h>

#include <inet/InetConfig.h>
#include <platform/CHIPDeviceLayer.h>
#include <transport/TransportMgr.h>
#include <transport/raw/UDP.h>

LOG_MODULE_DECLARE(app);

const char kPublishServicePayload[] = "chip-light-bulb";
const char kPublishDestAddr[] = "ff03::1";

using namespace ::chip;
using namespace ::chip::Inet;
using namespace ::chip::Transport;
using namespace ::chip::DeviceLayer;

void LightBulbPublishService::Init()
{
	mIsServiceStarted = false;

	/* Initialize timer */
	k_timer_init(&mPublishTimer, &PublishTimerHandler, nullptr);
	k_timer_user_data_set(&mPublishTimer, this);

	/* Initialize UDP endpoint */
	UdpListenParameters udpParams(chip::DeviceLayer::UDPEndPointManager());
	udpParams.SetListenPort(kServiceUDPPort);
	if (mUdp.Init(udpParams) != CHIP_NO_ERROR) {
		LOG_ERR("LightBulbPublishService initialization failed");
	}

	mMessageId = 0;
	IPAddress::FromString(kPublishDestAddr, mPublishDestAddr);
}

void LightBulbPublishService::Start(uint32_t aTimeoutInMs, uint32_t aIntervalInMs)
{
	if (!mIsServiceStarted) {
		if (aTimeoutInMs >= aIntervalInMs) {
			LOG_INF("Started Publish service");

			mPublishInterval = aIntervalInMs;
			/* Calculate number of publish iterations to do considering given timeout and interval values.
			 */
			mPublishIterations = aTimeoutInMs / aIntervalInMs;
			mIsServiceStarted = true;

			k_timer_start(&mPublishTimer, K_MSEC(aIntervalInMs), K_NO_WAIT);
		} else {
			LOG_ERR("Publish service cannot be started: service timeout is greater than interval");
		}
	} else {
		LOG_INF("Publish service is already running");
	}
}

void LightBulbPublishService::Stop()
{
	if (mIsServiceStarted) {
		LOG_INF("Stopped Publish service");

		k_timer_stop(&mPublishTimer);

		mIsServiceStarted = false;
		mMessageId = 0;
	} else {
		LOG_INF("Publish service is not running");
	}
}

void LightBulbPublishService::Publish()
{
	if (!chip::DeviceLayer::ConnectivityMgrImpl().IsThreadAttached()) {
		return;
	}

	const uint16_t payloadLength = sizeof(kPublishServicePayload);

	auto buffer = chip::System::PacketBufferHandle::NewWithData(kPublishServicePayload, payloadLength);
	if (!buffer.IsNull()) {
		if (mUdp.SendMessage(Transport::PeerAddress::UDP(mPublishDestAddr, kServiceUDPPort),
				     std::move(buffer)) == CHIP_NO_ERROR) {
			LOG_INF("LightBulbPublishService message sent successfully");
		} else {
			LOG_INF("LightBulbPublishService message sending failed");
		}
	}
}

void LightBulbPublishService::PublishTimerHandler(k_timer *aTimer)
{
	LightBulbPublishService *sLightBulbPublishService =
		reinterpret_cast<LightBulbPublishService *>(aTimer->user_data);
	if (sLightBulbPublishService->mPublishIterations > 0) {
		GetAppTask().PostEvent(AppEvent{ AppEvent::PublishLightBulbService });
		k_timer_start(&(sLightBulbPublishService->mPublishTimer),
			      K_MSEC(sLightBulbPublishService->mPublishInterval), K_NO_WAIT);
		sLightBulbPublishService->mPublishIterations--;
	} else {
		sLightBulbPublishService->Stop();
	}
}
```

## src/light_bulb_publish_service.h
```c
/*
 * Copyright (c) 2021 Nordic Semiconductor ASA
 *
 * SPDX-License-Identifier: LicenseRef-Nordic-5-Clause
 */

#pragma once

#include <inet/InetConfig.h>
#include <transport/raw/UDP.h>

#include <zephyr.h>

#include <string>

using namespace ::chip::Inet;
using namespace ::chip::Transport;

class LightBulbPublishService {
public:
	void Init();
	void Start(uint32_t aTimeoutInMs, uint32_t aIntervalInMs);
	void Stop();
	void Publish();

private:
	friend LightBulbPublishService &LightBulbPublishServ();

	static constexpr uint16_t kServiceUDPPort = 12345;

	bool mIsServiceStarted;
	uint32_t mPublishInterval;
	uint32_t mPublishIterations;
	k_timer mPublishTimer;
	UDP mUdp;
	uint32_t mMessageId;
	IPAddress mPublishDestAddr;

	static void PublishTimerHandler(k_timer *aTimer);
};
```

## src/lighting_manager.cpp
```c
/*
 * Copyright (c) 2021 Nordic Semiconductor ASA
 *
 * SPDX-License-Identifier: LicenseRef-Nordic-5-Clause
 */

#include "lighting_manager.h"

#include <drivers/pwm.h>
#include <logging/log.h>
#include <sys/util.h>
#include <zephyr.h>

LOG_MODULE_DECLARE(app);

LightingManager LightingManager::sLight;

int LightingManager::Init(const device *pwmDevice, uint32_t pwmChannel, uint8_t minLevel, uint8_t maxLevel)
{
	mState = State::On;
	mMinLevel = minLevel;
	mMaxLevel = maxLevel;
	mLevel = maxLevel;
	mPwmDevice = pwmDevice;
	mPwmChannel = pwmChannel;

	if (!device_is_ready(mPwmDevice)) {
		LOG_ERR("PWM device %s is not ready", mPwmDevice->name);
		return -ENODEV;
	}

	Set(false);
	return 0;
}

void LightingManager::SetCallbacks(LightingCallback_fn aActionInitiated_CB, LightingCallback_fn aActionCompleted_CB)
{
	mActionInitiated_CB = aActionInitiated_CB;
	mActionCompleted_CB = aActionCompleted_CB;
}

bool LightingManager::InitiateAction(Action aAction, uint8_t value, bool chipInitiated)
{
	bool actionInitiated = false;
	State newState;

	/* Initiate On/Off Action only when the previous one is complete. */
	if (mState == State::Off && aAction == Action::On) {
		actionInitiated = true;
		newState = State::On;
	} else if (mState == State::On && aAction == Action::Off) {
		actionInitiated = true;
		newState = State::Off;
	} else if (aAction == Action::Level && value != mLevel) {
		actionInitiated = true;
		newState = (value == 0) ? State::Off : State::On;
	}

	if (actionInitiated) {
		if (mActionInitiated_CB) {
			mActionInitiated_CB(aAction);
		}

		if (aAction == Action::On || aAction == Action::Off) {
			Set(newState == State::On);
		} else if (aAction == Action::Level) {
			SetLevel(value);
		}

		mChipInitiatedAction = chipInitiated;

		if (mActionCompleted_CB) {
			mActionCompleted_CB(aAction);
		}
	}

	return actionInitiated;
}

void LightingManager::SetLevel(uint8_t aLevel)
{
	LOG_INF("Setting brightness level to %u", aLevel);
	mLevel = aLevel;
	UpdateLight();
}

void LightingManager::Set(bool aOn)
{
	mState = aOn ? State::On : State::Off;
	UpdateLight();
}

void LightingManager::UpdateLight()
{
	constexpr uint32_t kPwmWidthUs = 20000u;
	const uint8_t maxEffectiveLevel = mMaxLevel - mMinLevel;
	const uint8_t effectiveLevel = mState == State::On ? MIN(mLevel - mMinLevel, maxEffectiveLevel) : 0;

	pwm_pin_set_usec(mPwmDevice, mPwmChannel, kPwmWidthUs, kPwmWidthUs * effectiveLevel / maxEffectiveLevel, 0);
}
```

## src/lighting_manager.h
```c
/*
 * Copyright (c) 2021 Nordic Semiconductor ASA
 *
 * SPDX-License-Identifier: LicenseRef-Nordic-5-Clause
 */

#pragma once

#include "app_event.h"

#include <cstdint>
#include <drivers/gpio.h>

class LightingManager {
public:
	enum class Action : uint8_t { On, Off, Level };

	enum class State : uint8_t { On, Off };

	using LightingCallback_fn = void (*)(Action);

	int Init(const device *pwmDevice, uint32_t pwmChannel, uint8_t minLevel, uint8_t maxLevel);
	bool IsTurnedOn() const { return mState == State::On; }
	uint8_t GetLevel() const { return mLevel; }
	bool IsActionChipInitiated() const { return mChipInitiatedAction; }
	bool InitiateAction(Action aAction, uint8_t value, bool chipInitiated);
	void SetCallbacks(LightingCallback_fn aActionInitiated_CB, LightingCallback_fn aActionCompleted_CB);

private:
	friend LightingManager &LightingMgr();
	State mState;
	uint8_t mMinLevel;
	uint8_t mMaxLevel;
	uint8_t mLevel;
	const device *mPwmDevice;
	uint32_t mPwmChannel;
	bool mChipInitiatedAction;

	LightingCallback_fn mActionInitiated_CB;
	LightingCallback_fn mActionCompleted_CB;

	void Set(bool aOn);
	void SetLevel(uint8_t aLevel);
	void UpdateLight();

	static LightingManager sLight;
};

inline LightingManager &LightingMgr(void)
{
	return LightingManager::sLight;
}
```

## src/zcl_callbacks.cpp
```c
/*
 * Copyright (c) 2021 Nordic Semiconductor ASA
 *
 * SPDX-License-Identifier: LicenseRef-Nordic-5-Clause
 */

#include <lib/support/logging/CHIPLogging.h>

#include "app_task.h"
#include "lighting_manager.h"

#include <app-common/zap-generated/ids/Attributes.h>
#include <app-common/zap-generated/ids/Clusters.h>
#include <app/ConcreteAttributePath.h>

using namespace ::chip;
using namespace ::chip::app::Clusters;

void MatterPostAttributeChangeCallback(const chip::app::ConcreteAttributePath &attributePath, uint8_t mask,
				       uint8_t type, uint16_t size, uint8_t *value)
{
	ClusterId clusterId = attributePath.mClusterId;
	AttributeId attributeId = attributePath.mAttributeId;

	if (clusterId == OnOff::Id && attributeId == OnOff::Attributes::OnOff::Id) {
		ChipLogProgress(Zcl, "Cluster OnOff: attribute OnOff set to %" PRIu8, *value);
		GetAppTask().PostEvent(AppEvent(*value ? AppEvent::On : AppEvent::Off, *value, true));
	} else if (clusterId == LevelControl::Id && attributeId == LevelControl::Attributes::CurrentLevel::Id) {
		ChipLogProgress(Zcl, "Cluster LevelControl: attribute CurrentLevel set to %" PRIu8, *value);
		GetAppTask().PostEvent(AppEvent(AppEvent::Level, *value, true));
	}
}

/** @brief OnOff Cluster Init
 *
 * This function is called when a specific cluster is initialized. It gives the
 * application an opportunity to take care of cluster initialization procedures.
 * It is called exactly once for each endpoint where cluster is present.
 *
 * @param endpoint   Ver.: always
 *
 * TODO Issue #3841
 * emberAfOnOffClusterInitCallback happens before the stack initialize the cluster
 * attributes to the default value.
 * The logic here expects something similar to the deprecated Plugins callback
 * emberAfPluginOnOffClusterServerPostInitCallback.
 *
 */
void emberAfOnOffClusterInitCallback(EndpointId endpoint)
{
	GetAppTask().UpdateClusterState();
}
```
